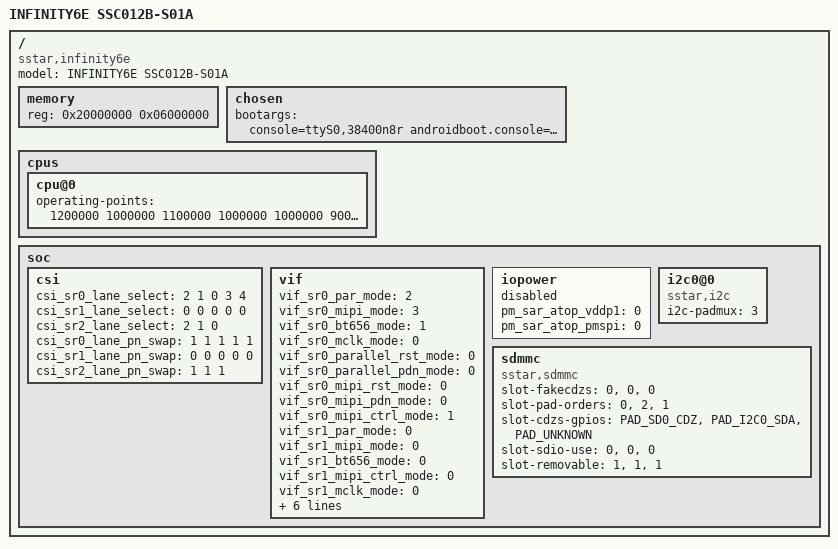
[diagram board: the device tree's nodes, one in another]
/*
 * Copyright (c) 2014 MundoReader S.L.
 * Author: Matthias Brugger <matthias.bgg@gmail.com>
 *
 * This program is free software; you can redistribute it and/or modify
 * it under the terms of the GNU General Public License as published by
 * the Free Software Foundation; either version 2 of the License, or
 * (at your option) any later version.
 *
 * This program is distributed in the hope that it will be useful,
 * but WITHOUT ANY WARRANTY; without even the implied warranty of
 * MERCHANTABILITY or FITNESS FOR A PARTICULAR PURPOSE.  See the
 * GNU General Public License for more details.
 */

 /*
 * Memory Layout
 * 0x20000000-0x24000000 64M Kernel
 * 0x24000000-0x24800000 8M  system
 * 0x24800000-0x24900000 1M  data
 * 0x24900000-0x25000000 7M  temp0
 * 0x25000000-0x28000000 48M temp1
 */
/dts-v1/;
#include "infinity6e.dtsi"
#include "infinity6e-padmux-qfn.dtsi"

/ {
    model = "INFINITY6E SSC012B-S01A";
    compatible = "sstar,infinity6e";

    memory {
        reg = <0x20000000 0x06000000>;
    };

    chosen {
        bootargs = "console=ttyS0,38400n8r androidboot.console=ttyS0 root=/dev/mtdblock0 init=/linuxrc LX_MEM=0x3ee0000 mma_heap=mma_heap_name0,miu=0,sz=0x2000000 mma_memblock_remove=1";
    };

    /*!!IMPORTANT!! The reserved memory must be 1MB aligned*/
    /*
    reserved-memory {
        #address-cells = <1>;
        #size-cells = <1>;
        ranges;

        cma0 {
            compatible = "shared-dma-pool";
            reusable;
            size = <0x04000000>;
            alignment = <0x1000>;
            linux,cma-default;
        };
    };
    */
    cpus {
          cpu@0 {
            	operating-points = <
                	/* kHz     uV */
                	1200000  1000000
                	1100000  1000000
                	1000000  900000
                	900000   900000
                	800000   900000
                	600000   900000
                	400000   900000
            	>;
          };
	};
    soc {
        /* mipi0 2+2 setting */
        csi {
            /* Config lane selection */
            csi_sr0_lane_select = <2 1 0 3 4>;
            csi_sr1_lane_select = <0 0 0 0 0>;
            csi_sr2_lane_select = <2 1 0>;
            /* Config lane P/N swap */
            csi_sr0_lane_pn_swap = <1 1 1 1 1>;
            csi_sr1_lane_pn_swap = <0 0 0 0 0>;
            csi_sr2_lane_pn_swap = <1 1 1>;
        };

        /* mipi0 2+2 setting */
        vif {
            /* Config sensor 0 pad mux */
            vif_sr0_par_mode = <2>;
            vif_sr0_mipi_mode = <3>;
            vif_sr0_bt656_mode = <1>;
            vif_sr0_mclk_mode = <0>;
            //vif_sr0_rst_mode  = <0>;
            //vif_sr0_pdn_mode  = <0>;
            vif_sr0_parallel_rst_mode  = <0>;
            vif_sr0_parallel_pdn_mode  = <0>;
            vif_sr0_mipi_rst_mode  = <0>;
            vif_sr0_mipi_pdn_mode  = <0>;
            vif_sr0_mipi_ctrl_mode = <1>;
            //vif_sr0_hvsync_mode  = <0>; /* Not used in I6E */
            //vif_sr0_pck_mode  = <0>; /* Not used in I6E */
            /* Config sensor 1 pad mux */
            vif_sr1_par_mode = <0>;
            vif_sr1_mipi_mode = <0>;
            vif_sr1_bt656_mode = <0>;
            vif_sr1_mipi_ctrl_mode = <0>;
            vif_sr1_mclk_mode = <0>;
            vif_sr1_rst_mode  = <0>;
            /* Config sensor 2 pad mux */
            vif_sr2_mipi_mode = <1>; /* MIPI sensor only */
            vif_sr2_mipi_ctrl_mode = <0>;
            vif_sr2_mclk_mode = <1>;
            vif_sr2_rst_mode  = <0>;

            vif_sr_gpio_puse_0 = <MDRV_PUSE_PWM1>; /* MDRV_PUSE_NA */
        };

        iopower {
            pm_sar_atop_vddp1 = <0>; /* 0: 1.8V 1: 3.3V */
            pm_sar_atop_pmspi = <0>; /* 0: 1.8V 1: 3.3V */
            status = "disabled";
        };

        i2c0@0{
            compatible = "sstar,i2c";
            /*
             * padmux: 1 -> PAD_I2C0_SCL, PAD_I2C0_SDA
             *         2 -> PAD_ETH_LED0, PAD_ETH_LED1
             *         3 -> PAD_GPIO6, PAD_GPIO7
             *         4 -> PAD_SR1_IO00, PAD_SR1_IO01
             *         5 -> PAD_GPIO12, PAD_GPIO13
            */
            i2c-padmux = <3>;
        };

        sdmmc {
            compatible = "sstar,sdmmc";
            slot-fakecdzs = <0>,<0>,<0>;
            //QFN-CFG
            slot-pad-orders = <0>,<2>,<1>;
            slot-cdzs-gpios = <PAD_SD0_CDZ>,<PAD_I2C0_SDA>,<PAD_UNKNOWN>;
            slot-sdio-use = <0>,<0>,<0>;
            slot-removable = <1>,<1>,<1>;
        };
    };
};
